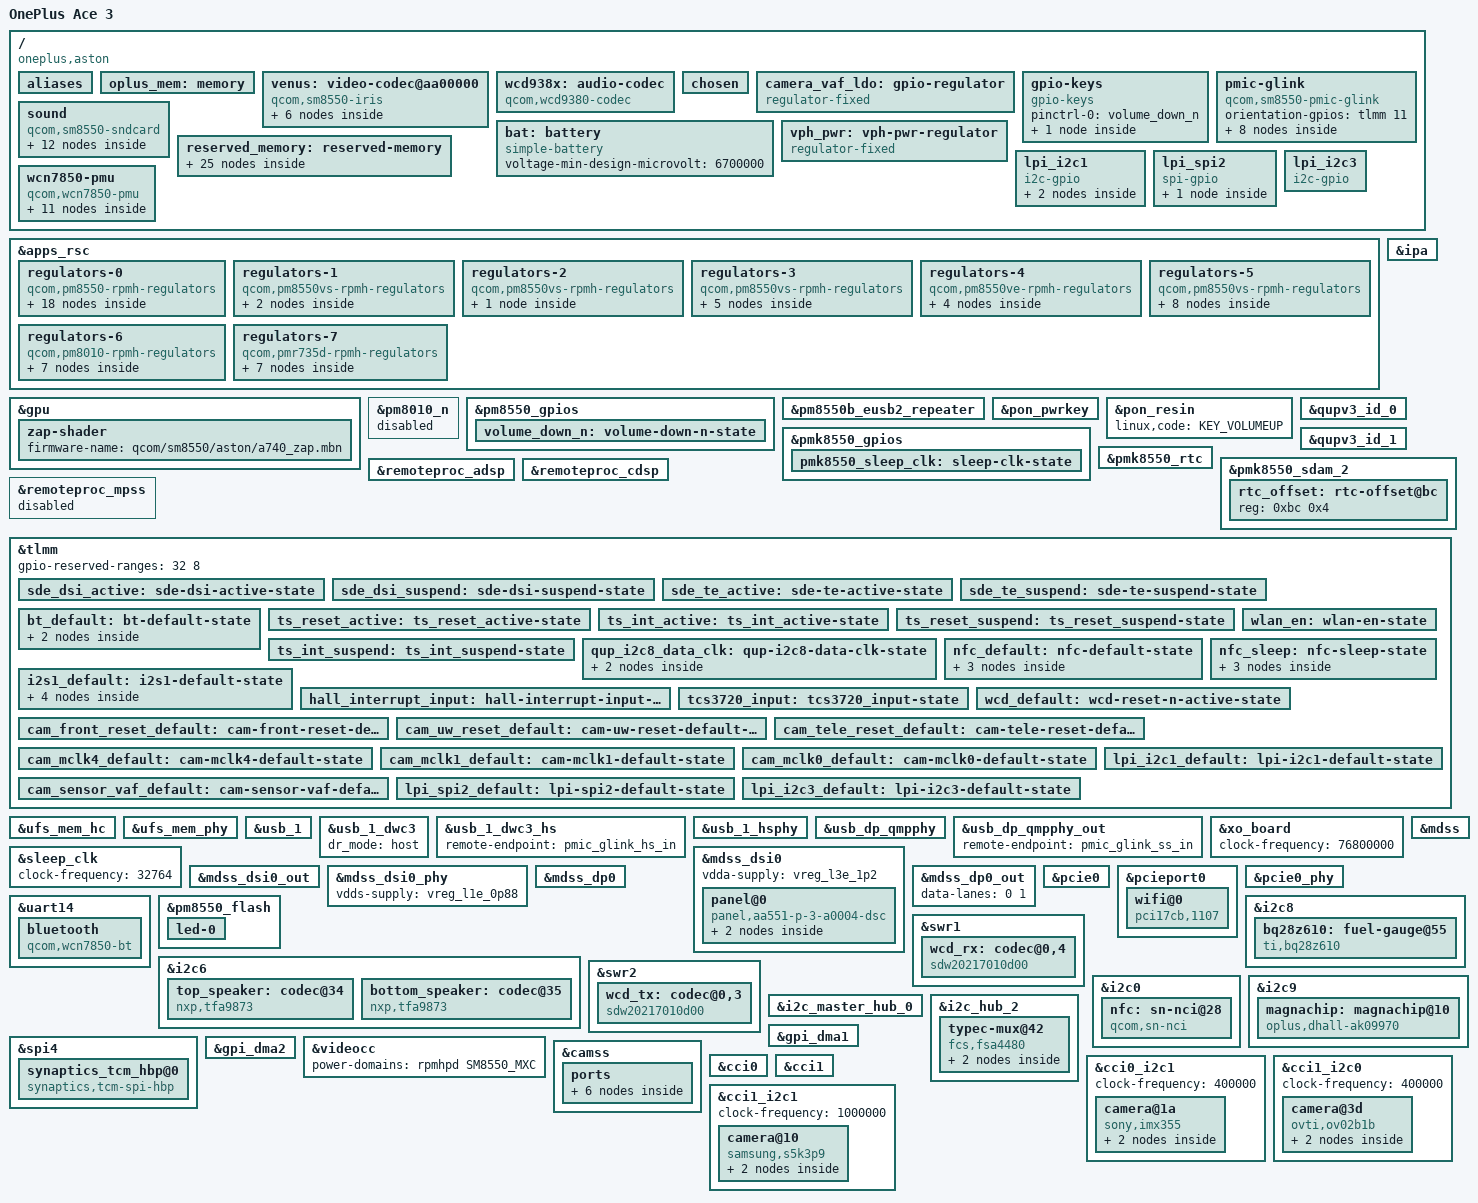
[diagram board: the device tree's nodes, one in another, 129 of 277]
// SPDX-License-Identifier: BSD-3-Clause
/*
 * Copyright (c) 2025, Shandorman <98683030+jiganomegsdfdf@users.noreply.github.com>
 */

/dts-v1/;

#include <dt-bindings/arm/qcom,ids.h>
#include <dt-bindings/regulator/qcom,rpmh-regulator.h>
#include <dt-bindings/leds/common.h>
#include <dt-bindings/interconnect/qcom,icc.h>
#include "sm8550.dtsi"
#include "pm8010.dtsi"
#include "pm8550.dtsi"
#include "pm8550b.dtsi"
#define PMK8550VE_SID 5
#include "pm8550ve.dtsi"
#include "pm8550vs.dtsi"
#include "pmk8550.dtsi"
#include "pmr735d_a.dtsi"

/delete-node/ &reserved_memory;

/ {
	model = "OnePlus Ace 3";
	compatible = "oneplus,aston", "qcom,sm8550";
	chassis-type = "handset";
	qcom,msm-id = <0x207 0x20000 0x207 0x10000 0x218 0x20000 0x218 0x10000>;
	qcom,board-id = <0x10008 0>;

	aliases {
		serial0 = &uart7;
		serial1 = &uart14;
	};
	
	oplus_mem: memory {
		ddr_device_type = <0x08>;
		device_type = "memory";
		reg = <0x00 0x80000000 0x00 0xe00000 0x00 0x811d0000 0x00 0x56e30000 0x00 0xd8140000 0x00 0x20000 0x00 0xd8800000 0x00 0x00 0x00 0xe1bb0000 0x00 0x1e450000 0x08 0x80000000 0x00 0x35700000 0x08 0xc0000000 0x01 0x40000000 0x0a 0x00 0x02 0x00>;
	};
	
	venus: video-codec@aa00000 {
		compatible = "qcom,sm8550-iris";
		reg = <0x0 0x0aa00000 0x0 0xf0000>;
		interrupts = <GIC_SPI 174 IRQ_TYPE_LEVEL_HIGH>;

		power-domains = <&videocc VIDEO_CC_MVS0C_GDSC>,
						<&videocc VIDEO_CC_MVS0_GDSC>,
						<&rpmhpd RPMHPD_MXC>,
						<&rpmhpd RPMHPD_MMCX>;
		power-domain-names = "venus", "vcodec0", "mxc", "mmcx";

		clocks = <&gcc GCC_VIDEO_AXI0_CLK>,
				 <&videocc VIDEO_CC_MVS0C_CLK>,
				 <&videocc VIDEO_CC_MVS0_CLK>;
		clock-names = "iface", "core", "vcodec0_core";

		interconnects = <&gem_noc MASTER_APPSS_PROC QCOM_ICC_TAG_ALWAYS
						 &config_noc SLAVE_VENUS_CFG QCOM_ICC_TAG_ALWAYS>,
						<&mmss_noc MASTER_VIDEO QCOM_ICC_TAG_ALWAYS
						 &mc_virt SLAVE_EBI1 QCOM_ICC_TAG_ALWAYS>;
		interconnect-names = "cpu-cfg", "video-mem";

		memory-region = <&video_mem>;

		resets = <&gcc GCC_VIDEO_AXI0_CLK_ARES>;
		reset-names = "bus";

		iommus = <&apps_smmu 0x1940 0x0000>,
				 <&apps_smmu 0x1947 0x0000>;
		dma-coherent;

		operating-points-v2 = <&iris_opp_table>;

		firmware-name = "qcom/sm8550/aston/vpu30_4v.mbn";

		iris_opp_table: opp-table {
			compatible = "operating-points-v2";

			opp-240000000 {
				opp-hz = /bits/ 64 <240000000>;
				required-opps = <&rpmhpd_opp_svs>,
								<&rpmhpd_opp_low_svs>;
			};

			opp-338000000 {
				opp-hz = /bits/ 64 <338000000>;
				required-opps = <&rpmhpd_opp_svs>,
								<&rpmhpd_opp_svs>;
			};

			opp-366000000 {
				opp-hz = /bits/ 64 <366000000>;
				required-opps = <&rpmhpd_opp_svs_l1>,
								<&rpmhpd_opp_svs_l1>;
			};

			opp-444000000 {
				opp-hz = /bits/ 64 <444000000>;
				required-opps = <&rpmhpd_opp_turbo>,
								<&rpmhpd_opp_turbo>;
			};

			opp-533333334 {
				opp-hz = /bits/ 64 <533333334>;
				required-opps = <&rpmhpd_opp_turbo_l1>,
								<&rpmhpd_opp_turbo_l1>;
			};
		};
	};

	wcd938x: audio-codec {
		compatible = "qcom,wcd9380-codec";
		
		pinctrl-names = "default";
		pinctrl-0 = <&wcd_default>;
		
		qcom,micbias1-microvolt = <2750000>;
		qcom,micbias2-microvolt = <2750000>;
		qcom,micbias3-microvolt = <2750000>;
		qcom,micbias4-microvolt = <2750000>;
		qcom,mbhc-buttons-vthreshold-microvolt = <75000 150000 237000 500000 500000 500000 500000 500000>;
		qcom,mbhc-headset-vthreshold-microvolt = <1700000>;
		qcom,mbhc-headphone-vthreshold-microvolt = <50000>;
		qcom,rx-device = <&wcd_rx>;
		qcom,tx-device = <&wcd_tx>;
		
		reset-gpios = <&tlmm 108 GPIO_ACTIVE_LOW>;
		
		vdd-buck-supply = <&vreg_l15b_1p8>;
		vdd-rxtx-supply = <&vreg_l15b_1p8>;
		vdd-io-supply = <&vreg_l15b_1p8>;
		vdd-mic-bias-supply = <&vreg_bob1>;
		
		#sound-dai-cells = <1>;
	};
	
	chosen {
		#address-cells = <2>;
		#size-cells = <2>;
		ranges;
	};

	camera_vaf_ldo: gpio-regulator {
		compatible = "regulator-fixed";
		regulator-name = "camera_vaf_ldo";
		regulator-min-microvolt = <2800000>;
		regulator-max-microvolt = <2800000>;
		regulator-enable-ramp-delay = <135>;
		enable-active-high;
		gpio = <&tlmm 52 0>;
		pinctrl-names = "default";
		pinctrl-0 = <&cam_sensor_vaf_default>;
	};

	gpio-keys {
		compatible = "gpio-keys";

		pinctrl-0 = <&volume_down_n>;
		pinctrl-names = "default";

		key-volume-down {
			label = "Volume Down";
			linux,code = <KEY_VOLUMEDOWN>;
			gpios = <&pm8550_gpios 6 GPIO_ACTIVE_LOW>;
			debounce-interval = <15>;
			linux,can-disable;
			wakeup-source;
		};
	};
	
	bat: battery {
		compatible = "simple-battery";
		voltage-min-design-microvolt = <6700000>;
	};

	pmic-glink {
		compatible = "qcom,sm8550-pmic-glink", "qcom,pmic-glink";
		#address-cells = <1>;
		#size-cells = <0>;
		orientation-gpios = <&tlmm 11 GPIO_ACTIVE_HIGH>;

		connector@0 {
			compatible = "usb-c-connector";
			reg = <0>;
			power-role = "dual";
			data-role = "dual";

			ports {
				#address-cells = <1>;
				#size-cells = <0>;

				port@0 {
					reg = <0>;

					pmic_glink_hs_in: endpoint {
						remote-endpoint = <&usb_1_dwc3_hs>;
					};
				};

				port@1 {
					reg = <1>;

					pmic_glink_ss_in: endpoint {
						remote-endpoint = <&usb_dp_qmpphy_out>;
					};
				};

				port@2 {
					reg = <2>;

					pmic_glink_sbu: endpoint {
						remote-endpoint = <&fsa4480_sbu_mux>;
					};
				};
			};
		};
	};
	
	sound {
		compatible = "qcom,sm8550-sndcard", "qcom,sm8450-sndcard";
		pinctrl-0 = <&i2s1_default>;
		pinctrl-names = "default";

		clocks = <&q6prmcc LPASS_CLK_ID_SEC_MI2S_IBIT LPASS_CLK_ATTRIBUTE_COUPLE_NO>;
		assigned-clocks = <&q6prmcc LPASS_CLK_ID_SEC_MI2S_IBIT LPASS_CLK_ATTRIBUTE_COUPLE_NO>;
		assigned-clock-rates = <1536000>;

		model = "astonsnd";
		audio-routing = "IN1_HPHL", "HPHL_OUT",
				"IN2_HPHR", "HPHR_OUT",
				"AMIC1", "MIC BIAS1",
				"AMIC2", "MIC BIAS2",
				"AMIC3", "MIC BIAS3",
				"AMIC4", "MIC BIAS4",
				"AMIC5", "MIC BIAS3",
				"TX SWR_INPUT0", "ADC1_OUTPUT",
				"TX SWR_INPUT1", "ADC2_OUTPUT",
				"TX SWR_INPUT0", "ADC3_OUTPUT",
				"TX SWR_INPUT1", "ADC4_OUTPUT";
		wcd-playback-dai-link {
			link-name = "WCD Playback";
			cpu {
				sound-dai = <&q6apmbedai RX_CODEC_DMA_RX_0>;
			};
			codec {
				sound-dai = <&wcd938x 0>, <&swr1 0>, <&lpass_rxmacro 0>;
			};
			platform {
				sound-dai = <&q6apm>;
			};
		};

		wcd-capture-dai-link {
			link-name = "WCD Capture";
			cpu {
				sound-dai = <&q6apmbedai TX_CODEC_DMA_TX_3>;
			};
			codec {
				sound-dai = <&wcd938x 1>, <&swr2 0>, <&lpass_txmacro 0>;
			};
			platform {
				sound-dai = <&q6apm>;
			};
		};

		secondary-i2s-dai-link {
			link-name = "Secondary MI2S Playback";

			cpu {
				sound-dai = <&q6apmbedai SECONDARY_MI2S_RX>;
			};

			platform {
				sound-dai = <&q6apm>;
			};

			codec {
				sound-dai = <&top_speaker>, <&bottom_speaker>;
			};
		};
	};
	
	reserved_memory: reserved-memory {
		#address-cells = <2>;
		#size-cells = <2>;
		ranges;
		
		hyp_mem: hyp-region@80000000 {
			no-map;
			reg = <0x00 0x80000000 0x00 0xa00000>;
		};

		cpusys_vm_mem: cpusys-vm-region@80a00000 {
			no-map;
			reg = <0x00 0x80a00000 0x00 0x400000>;
		};

		/* merged xbl_dt_log, xbl_ramdump, aop_image */
		xbl_dt_log_merged_mem: xbl-dt-log-merged-region@81a00000 {
			no-map;
			reg = <0x00 0x81a00000 0x00 0x260000>;
		};

		aop_cmd_db_mem: aop-cmd-db-region@81c60000 {
			compatible = "qcom,cmd-db";
			no-map;
			reg = <0x00 0x81c60000 0x00 0x20000>;
		};

		/* merged aop_config, tme_crash_dump, tme_log, uefi_log */
		aop_config_merged_mem: aop-config-merged-region@81c80000 {
			no-map;
			reg = <0x00 0x81c80000 0x00 0x74000>;
		};
		
		chipinfo_region: chipinfo-region@81cf4000 {
			no-map;
			reg = <0x00 0x81cf4000 0x00 0x1000>;
		};

		/* secdata region can be reused by apps */
		smem: smem@81d00000 {
			no-map;
			reg = <0x00 0x81d00000 0x00 0x200000>;
			hwlocks = <&tcsr_mutex 3>;
			compatible = "qcom,smem";
		};

		adsp_mhi_mem: adsp-mhi-region@81f00000 {
			no-map;
			reg = <0x00 0x81f00000 0x00 0x20000>;
		};
		
		tz_stat_region: tz-stat-region@82700000 {
			no-map;
			reg = <0x00 0x82700000 0x00 0x100000>;
		};
		
		mpss_mem: mpss-region@8a800000 {
			no-map;
			reg = <0x00 0x8a800000 0x00 0x10800000>;
		};

		q6_mpss_dtb_mem: q6-mpss-dtb-region@9b000000 {
			no-map;
			reg = <0x00 0x9b000000 0x00 0x80000>;
		};

		ipa_fw_mem: ipa-fw-region@9b080000 {
			no-map;
			reg = <0x00 0x9b080000 0x00 0x10000>;
		};

		ipa_gsi_mem: ipa-gsi-region@9b090000 {
			no-map;
			reg = <0x00 0x9b090000 0x00 0xa000>;
		};

		gpu_micro_code_mem: gpu-micro-code-region@9b09a000 {
			no-map;
			reg = <0x00 0x9b09a000 0x00 0x2000>;
		};
		
		video_mem: video-region@9bb00000 {
			no-map;
			reg = <0x00 0x9bb00000 0x00 0x700000>;
		};

		cdsp_mem: cdsp-region@9c900000 {
			no-map;
			reg = <0x00 0x9c900000 0x00 0x2000000>;
		};

		q6_cdsp_dtb_mem: q6-cdsp-dtb-region@9e900000 {
			no-map;
			reg = <0x00 0x9e900000 0x00 0x80000>;
		};

		q6_adsp_dtb_mem: q6-adsp-dtb-region@9e980000 {
			no-map;
			reg = <0x00 0x9e980000 0x00 0x80000>;
		};

		adspslpi_mem: adspslpi-region@9ea00000 {
			no-map;
			reg = <0x00 0x9ea00000 0x00 0x4880000>;
		};

		mpss_dsm_mem: mpss-dsm-region@d4d00000 {
			no-map;
			reg = <0x00 0xd4d00000 0x00 0x3300000>;
		};

		xbl_sc_mem: xbl-sc-region@d8100000 {
			no-map;
			reg = <0x00 0xd8100000 0x00 0x40000>;
		};

		cpucp_fw_mem: cpucp-fw-region@d8140000 {
			no-map;
			reg = <0x00 0xd8140000 0x00 0x1c0000>;
		};

		qtee_mem: qtee-region@d8300000 {
			no-map;
			reg = <0x00 0xd8300000 0x00 0x500000>;
		};

		hwfence_shbuf: hwfence-shbuf-region@e6440000 {
			no-map;
			reg = <0x00 0xe6440000 0x00 0x2dd000>;
		};

		rmtfs_mem: rmtfs-region@e8100000 {
			compatible = "qcom,rmtfs-mem";
			reg = <0x0 0xe8100000 0x0 0x280000>;
			no-map;

			qcom,client-id = <1>;
			qcom,vmid = <QCOM_SCM_VMID_MSS_MSA>;
		};
	};

	vph_pwr: vph-pwr-regulator {
		compatible = "regulator-fixed";
		regulator-name = "vph_pwr";
		regulator-min-microvolt = <3700000>;
		regulator-max-microvolt = <3700000>;

		regulator-always-on;
		regulator-boot-on;
	};

	lpi_i2c1 {
		compatible = "i2c-gpio";
		#address-cells = <1>;
		#size-cells = <0>;
		pinctrl-0 = <&lpi_i2c1_default>;
		pinctrl-names = "default";

		sda-gpios = <&tlmm 190 (GPIO_ACTIVE_HIGH|GPIO_OPEN_DRAIN)>;
		scl-gpios = <&tlmm 191 (GPIO_ACTIVE_HIGH|GPIO_OPEN_DRAIN)>;
		
		mmc56x3@30 {
			reg = <0x30>;
			compatible = "memsic,mmc56x3";
		};
		
		tcs3720@39 {
			reg = <0x39>;
			compatible = "tcs3720";
			interrupt-parent = <&tlmm>;
			interrupts = <16 IRQ_TYPE_EDGE_FALLING>;
		};
	};
	
	lpi_spi2 {
		compatible = "spi-gpio";
		#address-cells = <1>;
		#size-cells = <0>;
		pinctrl-0 = <&lpi_spi2_default>;
		pinctrl-names = "default";

		miso-gpios = <&tlmm 192 GPIO_ACTIVE_HIGH>;
		mosi-gpios = <&tlmm 193 GPIO_ACTIVE_HIGH>;
		sck-gpios = <&tlmm 194 GPIO_ACTIVE_HIGH>;
		cs-gpios = <&tlmm 195 GPIO_ACTIVE_HIGH>;
		num-chipselects = <1>;

		bmi26x@0 {
			reg = <0>;
			compatible = "bosch,bmi260";
			spi-max-frequency = <9600000>;
			interrupt-parent = <&tlmm>;
			interrupts = <84 IRQ_TYPE_LEVEL_HIGH>;
			vdd-supply = <&vreg_l1b_1p8>;
			vddio-supply = <&vreg_l1b_1p8>;
		};
	};
	
	lpi_i2c3 {
		compatible = "i2c-gpio";
		#address-cells = <1>;
		#size-cells = <0>;
		pinctrl-0 = <&lpi_i2c3_default>;
		pinctrl-names = "default";

		sda-gpios = <&tlmm 196 (GPIO_ACTIVE_HIGH|GPIO_OPEN_DRAIN)>;
		scl-gpios = <&tlmm 197 (GPIO_ACTIVE_HIGH|GPIO_OPEN_DRAIN)>;
	};
	
	wcn7850-pmu {
		compatible = "qcom,wcn7850-pmu";

		pinctrl-names = "default";
		pinctrl-0 = <&wlan_en>, <&bt_default>, <&pmk8550_sleep_clk>;

		wlan-enable-gpios = <&tlmm 80 GPIO_ACTIVE_HIGH>;
		bt-enable-gpios = <&tlmm 81 GPIO_ACTIVE_HIGH>;

		vdd-supply = <&vreg_s5g_0p8>;
		vddio-supply = <&vreg_l15b_1p8>; 
		vddaon-supply = <&vreg_s2g_0p8>;
		vdddig-supply = <&vreg_s4e_0p9>;
		vddrfa1p2-supply = <&vreg_s4g_1p3>;
		vddrfa1p8-supply = <&vreg_s6g_1p8>;

		regulators {
			vreg_pmu_rfa_cmn: ldo0 {
				regulator-name = "vreg_pmu_rfa_cmn";
			};

			vreg_pmu_aon_0p59: ldo1 {
				regulator-name = "vreg_pmu_aon_0p59";
			};

			vreg_pmu_wlcx_0p8: ldo2 {
				regulator-name = "vreg_pmu_wlcx_0p8";
			};

			vreg_pmu_wlmx_0p85: ldo3 {
				regulator-name = "vreg_pmu_wlmx_0p85";
			};

			vreg_pmu_btcmx_0p85: ldo4 {
				regulator-name = "vreg_pmu_btcmx_0p85";
			};

			vreg_pmu_rfa_0p8: ldo5 {
				regulator-name = "vreg_pmu_rfa_0p8";
			};

			vreg_pmu_rfa_1p2: ldo6 {
				regulator-name = "vreg_pmu_rfa_1p2";
			};

			vreg_pmu_rfa_1p8: ldo7 {
				regulator-name = "vreg_pmu_rfa_1p8";
			};

			vreg_pmu_pcie_0p9: ldo8 {
				regulator-name = "vreg_pmu_pcie_0p9";
			};

			vreg_pmu_pcie_1p8: ldo9 {
				regulator-name = "vreg_pmu_pcie_1p8";
			};
		};
	};
};

&apps_rsc {
	regulators-0 {
		compatible = "qcom,pm8550-rpmh-regulators";
		qcom,pmic-id = "b";

		vdd-bob1-supply = <&vph_pwr>;
		vdd-bob2-supply = <&vph_pwr>;
		vdd-l1-l4-l10-supply = <&vreg_s6g_1p8>;
		vdd-l2-l13-l14-supply = <&vreg_bob1>;
		vdd-l3-supply = <&vreg_s4g_1p3>;
		vdd-l5-l16-supply = <&vreg_bob1>;
		vdd-l6-l7-supply = <&vreg_bob1>;
		vdd-l8-l9-supply = <&vreg_bob1>;
		vdd-l11-supply = <&vreg_s4g_1p3>;
		vdd-l12-supply = <&vreg_s6g_1p8>;
		vdd-l15-supply = <&vreg_s6g_1p8>;
		vdd-l17-supply = <&vreg_bob2>;

		vreg_bob1: bob1 {
			regulator-name = "vreg_bob1";
			regulator-min-microvolt = <3008000>;
			regulator-max-microvolt = <3960000>;
			regulator-initial-mode = <RPMH_REGULATOR_MODE_HPM>;
		};

		vreg_bob2: bob2 {
			regulator-name = "vreg_bob2";
			regulator-min-microvolt = <2720000>;
			regulator-max-microvolt = <3008000>;
			regulator-initial-mode = <RPMH_REGULATOR_MODE_HPM>;
		};

		vreg_l1b_1p8: ldo1 {
			regulator-name = "vreg_l1b_1p8";
			regulator-min-microvolt = <1800000>;
			regulator-max-microvolt = <1800000>;
			regulator-initial-mode = <RPMH_REGULATOR_MODE_HPM>;
		};

		vreg_l2b_3p0: ldo2 {
			regulator-name = "vreg_l2b_3p0";
			regulator-min-microvolt = <3008000>;
			regulator-max-microvolt = <3008000>;
			regulator-initial-mode = <RPMH_REGULATOR_MODE_HPM>;
		};

		vreg_l4b_1p8: ldo4 {
			regulator-name = "vreg_l4b_1p8";
			regulator-min-microvolt = <1800000>;
			regulator-max-microvolt = <1800000>;
			regulator-initial-mode = <RPMH_REGULATOR_MODE_HPM>;
		};

		vreg_l5b_3p1: ldo5 {
			regulator-name = "vreg_l5b_3p1";
			regulator-min-microvolt = <3104000>;
			regulator-max-microvolt = <3104000>;
			regulator-initial-mode = <RPMH_REGULATOR_MODE_HPM>;
		};

		vreg_l6b_1p8: ldo6 {
			regulator-name = "vreg_l6b_1p8";
			regulator-min-microvolt = <1800000>;
			regulator-max-microvolt = <3008000>;
			regulator-initial-mode = <RPMH_REGULATOR_MODE_HPM>;
		};

		vreg_l7b_1p8: ldo7 {
			regulator-name = "vreg_l7b_1p8";
			regulator-min-microvolt = <1800000>;
			regulator-max-microvolt = <3008000>;
			regulator-initial-mode = <RPMH_REGULATOR_MODE_HPM>;
		};

		vreg_l8b_1p8: ldo8 {
			regulator-name = "vreg_l8b_1p8";
			regulator-min-microvolt = <1800000>;
			regulator-max-microvolt = <1800000>;
			regulator-initial-mode = <RPMH_REGULATOR_MODE_HPM>;
			regulator-always-on;
			regulator-boot-on;
		};

		vreg_l9b_3p3: ldo9 {
			regulator-name = "vreg_l9b_3p3";
			regulator-min-microvolt = <2960000>;
			regulator-max-microvolt = <3008000>;
			regulator-initial-mode = <RPMH_REGULATOR_MODE_HPM>;
		};

		vreg_l10b_1p8: ldo10 {
			regulator-name = "vreg_l10b_1p8";
			regulator-min-microvolt = <1800000>;
			regulator-max-microvolt = <1800000>;
			regulator-initial-mode = <RPMH_REGULATOR_MODE_HPM>;
			regulator-always-on;
		};

		vreg_l11b_1p2: ldo11 {
			regulator-name = "vreg_l11b_1p2";
			regulator-min-microvolt = <1200000>;
			regulator-max-microvolt = <1504000>;
			regulator-initial-mode = <RPMH_REGULATOR_MODE_HPM>;
		};

		vreg_l12b_1p8: ldo12 {
			regulator-name = "vreg_l12b_1p8";
			regulator-min-microvolt = <1800000>;
			regulator-max-microvolt = <1800000>;
			regulator-initial-mode = <RPMH_REGULATOR_MODE_HPM>;
		};

		vreg_l13b_3p3: ldo13 {
			regulator-name = "vreg_l13b_3p3";
			regulator-min-microvolt = <3000000>;
			regulator-max-microvolt = <3200000>;
			regulator-initial-mode = <RPMH_REGULATOR_MODE_HPM>;
		};

		vreg_l14b_3p2: ldo14 {
			regulator-name = "vreg_l14b_3p2";
			regulator-min-microvolt = <2800000>;
			regulator-max-microvolt = <3200000>;
			regulator-initial-mode = <RPMH_REGULATOR_MODE_HPM>;
		};
		
		vreg_l15b_1p8: ldo15 {
			regulator-name = "vreg_l15b_1p8";
			regulator-min-microvolt = <1800000>;
			regulator-max-microvolt = <1800000>;
			regulator-initial-mode = <RPMH_REGULATOR_MODE_HPM>;
			regulator-always-on;
		};

		vreg_l16b_2p8: ldo16 {
			regulator-name = "vreg_l16b_2p8";
			regulator-min-microvolt = <2800000>;
			regulator-max-microvolt = <2800000>;
			regulator-initial-mode = <RPMH_REGULATOR_MODE_HPM>;
		};

		vreg_l17b_2p5: ldo17 {
			regulator-name = "vreg_l17b_2p5";
			regulator-min-microvolt = <2504000>;
			regulator-max-microvolt = <2504000>;
			regulator-initial-mode = <RPMH_REGULATOR_MODE_HPM>;
		};
	};

	regulators-1 {
		compatible = "qcom,pm8550vs-rpmh-regulators";
		qcom,pmic-id = "c";

		vdd-l3-supply = <&vreg_s4e_0p9>;
		
		
		vreg_l1c_0p91: ldo1 {
			regulator-name = "vreg_l1c_0p9";
			regulator-min-microvolt = <1200000>;
			regulator-max-microvolt = <1200000>;
			regulator-initial-mode = <RPMH_REGULATOR_MODE_HPM>;
		};

		vreg_l3c_0p91: ldo3 {
			regulator-name = "vreg_l3c_0p9";
			regulator-min-microvolt = <880000>;
			regulator-max-microvolt = <912000>;
			regulator-initial-mode = <RPMH_REGULATOR_MODE_HPM>;
		};
	};

	regulators-2 {
		compatible = "qcom,pm8550vs-rpmh-regulators";
		qcom,pmic-id = "d";

		vdd-l1-supply = <&vreg_s4e_0p9>;

		vreg_l1d_0p88: ldo1 {
			regulator-name = "vreg_l1d_0p88";
			regulator-min-microvolt = <880000>;
			regulator-max-microvolt = <920000>;
			regulator-initial-mode = <RPMH_REGULATOR_MODE_HPM>;
		};
	};

	regulators-3 {
		compatible = "qcom,pm8550vs-rpmh-regulators";
		qcom,pmic-id = "e";

		vdd-l1-supply = <&vreg_s4e_0p9>;
		vdd-l2-supply = <&vreg_s4e_0p9>;
		vdd-l3-supply = <&vreg_s4g_1p3>;
		vdd-s4-supply = <&vph_pwr>;
		vdd-s5-supply = <&vph_pwr>;

		vreg_s4e_0p9: smps4 {
			regulator-name = "vreg_s4e_0p9";
			regulator-min-microvolt = <904000>;
			regulator-max-microvolt = <984000>;
			regulator-initial-mode = <RPMH_REGULATOR_MODE_HPM>;
		};

		vreg_s5e_1p1: smps5 {
			regulator-name = "vreg_s5e_1p1";
			regulator-min-microvolt = <1008000>;
			regulator-max-microvolt = <1120000>;
			regulator-initial-mode = <RPMH_REGULATOR_MODE_HPM>;
		};

		vreg_l1e_0p88: ldo1 {
			regulator-name = "vreg_l1e_0p88";
			regulator-min-microvolt = <880000>;
			regulator-max-microvolt = <912000>;
			regulator-initial-mode = <RPMH_REGULATOR_MODE_HPM>;
		};

		vreg_l2e_0p9: ldo2 {
			regulator-name = "vreg_l2e_0p9";
			regulator-min-microvolt = <864000>;
			regulator-max-microvolt = <970000>;
			regulator-initial-mode = <RPMH_REGULATOR_MODE_HPM>;
		};

		vreg_l3e_1p2: ldo3 {
			regulator-name = "vreg_l3e_1p2";
			regulator-min-microvolt = <1200000>;
			regulator-max-microvolt = <1200000>;
			regulator-initial-mode = <RPMH_REGULATOR_MODE_HPM>;
		};
	};

	regulators-4 {
		compatible = "qcom,pm8550ve-rpmh-regulators";
		qcom,pmic-id = "f";

		vdd-l1-supply = <&vreg_s4e_0p9>;
		vdd-l2-supply = <&vreg_s4e_0p9>;
		vdd-l3-supply = <&vreg_s4e_0p9>;
		vdd-s4-supply = <&vph_pwr>;

		vreg_s4f_0p5: smps4 {
			regulator-name = "vreg_s4f_0p5";
			regulator-min-microvolt = <300000>;
			regulator-max-microvolt = <700000>;
			regulator-initial-mode = <RPMH_REGULATOR_MODE_HPM>;
		};

		vreg_l1f_0p9: ldo1 {
			regulator-name = "vreg_l1f_0p9";
			regulator-min-microvolt = <880000>;
			regulator-max-microvolt = <912000>;
			regulator-initial-mode = <RPMH_REGULATOR_MODE_HPM>;
		};

		vreg_l2f_0p88: ldo2 {
			regulator-name = "vreg_l2f_0p88";
			regulator-min-microvolt = <880000>;
			regulator-max-microvolt = <912000>;
			regulator-initial-mode = <RPMH_REGULATOR_MODE_HPM>;
		};

		vreg_l3f_0p91: ldo3 {
			regulator-name = "vreg_l3f_0p91";
			regulator-min-microvolt = <880000>;
			regulator-max-microvolt = <912000>;
			regulator-initial-mode = <RPMH_REGULATOR_MODE_HPM>;
		};
	};

	regulators-5 {
		compatible = "qcom,pm8550vs-rpmh-regulators";
		qcom,pmic-id = "g";

		vdd-l1-supply = <&vreg_s4g_1p3>;
		vdd-l2-supply = <&vreg_s4g_1p3>;
		vdd-l3-supply = <&vreg_s4g_1p3>;
		vdd-s1-supply = <&vph_pwr>;
		vdd-s2-supply = <&vph_pwr>;
		vdd-s3-supply = <&vph_pwr>;
		vdd-s4-supply = <&vph_pwr>;
		vdd-s5-supply = <&vph_pwr>;
		vdd-s6-supply = <&vph_pwr>;

		vreg_s1g_1p2: smps1 {
			regulator-name = "vreg_s1g_1p2";
			regulator-min-microvolt = <1200000>;
			regulator-max-microvolt = <1300000>;
			regulator-initial-mode = <RPMH_REGULATOR_MODE_HPM>;
		};

		vreg_s2g_0p8: smps2 {
			regulator-name = "vreg_s2g_0p8";
			regulator-min-microvolt = <500000>;
			regulator-max-microvolt = <1036000>;
			regulator-initial-mode = <RPMH_REGULATOR_MODE_HPM>;
		};

		vreg_s4g_1p3: smps4 {
			regulator-name = "vreg_s4g_1p3";
			regulator-min-microvolt = <1200000>;
			regulator-max-microvolt = <1352000>;
			regulator-initial-mode = <RPMH_REGULATOR_MODE_HPM>;
		};

		vreg_s5g_0p8: smps5 {
			regulator-name = "vreg_s5g_0p8";
			regulator-min-microvolt = <500000>;
			regulator-max-microvolt = <1004000>;
			regulator-initial-mode = <RPMH_REGULATOR_MODE_HPM>;
		};

		vreg_s6g_1p8: smps6 {
			regulator-name = "vreg_s6g_1p8";
			regulator-min-microvolt = <1800000>;
			regulator-max-microvolt = <2000000>;
			regulator-initial-mode = <RPMH_REGULATOR_MODE_HPM>;
		};

		vreg_l1g_1p2: ldo1 {
			regulator-name = "vreg_l1g_1p2";
			regulator-min-microvolt = <1144000>;
			regulator-max-microvolt = <1256000>;
			regulator-initial-mode = <RPMH_REGULATOR_MODE_HPM>;
		};

		vreg_l2g_1p2: ldo2 {
			regulator-name = "vreg_l2g_1p2";
			regulator-min-microvolt = <1056000>;
			regulator-max-microvolt = <1056000>;
			regulator-initial-mode = <RPMH_REGULATOR_MODE_HPM>;
		};

		vreg_l3g_1p2: ldo3 {
			regulator-name = "vreg_l3g_1p2";
			regulator-min-microvolt = <1200000>;
			regulator-max-microvolt = <1200000>;
			regulator-initial-mode = <RPMH_REGULATOR_MODE_HPM>;
		};
	};

	regulators-6 {
		compatible = "qcom,pm8010-rpmh-regulators";
		qcom,pmic-id = "m";

		vdd-l1-l2-supply = <&vreg_s4g_1p3>;
		vdd-l3-l4-supply = <&vreg_bob2>;
		vdd-l5-supply = <&vreg_s6g_1p8>;
		vdd-l6-supply = <&vreg_s6g_1p8>;
		vdd-l7-supply = <&vreg_bob1>;

		vreg_l1m_1p2: ldo1 {
			regulator-name = "vreg_l1m_1p2";
			regulator-min-microvolt = <1200000>;
			regulator-max-microvolt = <1200000>;
			regulator-initial-mode = <RPMH_REGULATOR_MODE_HPM>;
		};

		vreg_l2m_1p08: ldo2 {
			regulator-name = "vreg_l2m_1p08";
			regulator-min-microvolt = <1200000>;
			regulator-max-microvolt = <1200000>;
			regulator-initial-mode = <RPMH_REGULATOR_MODE_HPM>;
		};

		vreg_l3m_2p8: ldo3 {
			regulator-name = "vreg_l3m_2p8";
			regulator-min-microvolt = <2800000>;
			regulator-max-microvolt = <2800000>;
			regulator-initial-mode = <RPMH_REGULATOR_MODE_HPM>;
		};

		vreg_l4m_2p8: ldo4 {
			regulator-name = "vreg_l4m_2p8";
			regulator-min-microvolt = <2800000>;
			regulator-max-microvolt = <2800000>;
			regulator-initial-mode = <RPMH_REGULATOR_MODE_HPM>;
		};

		vreg_l5m_1p8: ldo5 {
			regulator-name = "vreg_l5m_1p8";
			regulator-min-microvolt = <1800000>;
			regulator-max-microvolt = <1800000>;
			regulator-initial-mode = <RPMH_REGULATOR_MODE_HPM>;
		};

		vreg_l6m_2p8: ldo6 {
			regulator-name = "vreg_l6m_2p8";
			regulator-min-microvolt = <2848000>;
			regulator-max-microvolt = <2848000>;
			regulator-initial-mode = <RPMH_REGULATOR_MODE_HPM>;
		};

		vreg_l7m_2p85: ldo7 {
			regulator-name = "vreg_l7m_2p85";
			regulator-min-microvolt = <2800000>;
			regulator-max-microvolt = <2800000>;
			regulator-initial-mode = <RPMH_REGULATOR_MODE_HPM>;
		};
	};

	regulators-7 {
		compatible = "qcom,pmr735d-rpmh-regulators";
		qcom,pmic-id = "k";

		vdd-l1-l2-l5-supply = <&vreg_s2g_0p8>;
		vdd-l3-l4-supply = <&vreg_s1g_1p2>;
		vdd-l6-supply  = <&vreg_s6g_1p8>;
		vdd-l7-supply = <&vreg_s1g_1p2>;

		vreg_l1k_0p4: ldo1 {
			regulator-name = "vreg_l1k_0p4";
			regulator-min-microvolt = <400000>;
			regulator-max-microvolt = <900000>;
			regulator-initial-mode = <RPMH_REGULATOR_MODE_HPM>;
		};

		vreg_l2k_0p5: ldo2 {
			regulator-name = "vreg_l2k_0p5";
			regulator-min-microvolt = <500000>;
			regulator-max-microvolt = <900000>;
			regulator-initial-mode = <RPMH_REGULATOR_MODE_HPM>;
		};

		vreg_l3k_0p88: ldo3 {
			regulator-name = "vreg_l3k_0p88";
			regulator-min-microvolt = <880000>;
			regulator-max-microvolt = <912000>;
			regulator-initial-mode = <RPMH_REGULATOR_MODE_HPM>;
		};

		vreg_l4k_1p2: ldo4 {
			regulator-name = "vreg_l4k_1p2";
			regulator-min-microvolt = <1200000>;
			regulator-max-microvolt = <1200000>;
			regulator-initial-mode = <RPMH_REGULATOR_MODE_HPM>;
		};

		vreg_l5k_0p8: ldo5 {
			regulator-name = "vreg_l5k_0p8";
			regulator-min-microvolt = <800000>;
			regulator-max-microvolt = <800000>;
			regulator-initial-mode = <RPMH_REGULATOR_MODE_HPM>;
		};

		vreg_l6k_1p77: ldo6 {
			regulator-name = "vreg_l6k_1p77";
			regulator-min-microvolt = <1776000>;
			regulator-max-microvolt = <1900000>;
			regulator-initial-mode = <RPMH_REGULATOR_MODE_HPM>;
		};

		vreg_l7k_1p2: ldo7 {
			regulator-name = "vreg_l7k_1p2";
			regulator-min-microvolt = <1200000>;
			regulator-max-microvolt = <1200000>;
			regulator-initial-mode = <RPMH_REGULATOR_MODE_HPM>;
		};
	};
};



&ipa {
	qcom,gsi-loader = "self";
	memory-region = <&ipa_fw_mem>;
	firmware-name = "qcom/sm8550/aston/ipa_fws.mbn";
	status = "okay";
};

&gpu {
	status = "okay";

	zap-shader {
		firmware-name = "qcom/sm8550/aston/a740_zap.mbn";
	};
};

&pm8010_n {
	status = "disabled";
};

&pm8550_gpios {
	volume_down_n: volume-down-n-state {
		pins = "gpio6";
		function = "normal";
		power-source = <1>;
		bias-pull-up;
		input-enable;
	};
};

&pm8550b_eusb2_repeater {
	vdd18-supply = <&vreg_l15b_1p8>;
	vdd3-supply = <&vreg_l5b_3p1>;
};

&pon_pwrkey {
	status = "okay";
	interrupts = <0x0 0x13 0x7 IRQ_TYPE_EDGE_BOTH>;
    linux,code = <KEY_POWER>;
};

&pon_resin {
	linux,code = <KEY_VOLUMEUP>;

	status = "okay";
};

&pmk8550_gpios {
	pmk8550_sleep_clk: sleep-clk-state {
		pins = "gpio3";
		function = "func1";
		input-disable;
		output-enable;
		bias-disable;
		power-source = <0>;
	};
};

&qupv3_id_0 {
	status = "okay";
};

&qupv3_id_1 {
	status = "okay";
};

&pmk8550_rtc {
	nvmem-cells = <&rtc_offset>;
	nvmem-cell-names = "offset";
};

&pmk8550_sdam_2 {
	rtc_offset: rtc-offset@bc {
		reg = <0xbc 0x4>;
	};
};

&remoteproc_adsp {
	firmware-name = "qcom/sm8550/aston/adsp.mbn",
			"qcom/sm8550/aston/adsp_dtb.mbn";
	status = "okay";
};

&remoteproc_cdsp {
	firmware-name = "qcom/sm8550/aston/cdsp.mbn",
			"qcom/sm8550/aston/cdsp_dtb.mbn";
	status = "okay";
};

&remoteproc_mpss {
	firmware-name = "qcom/sm8550/aston/modem.mbn",
			"qcom/sm8550/aston/modem_dtb.mbn";
	status = "disabled";
};

&tlmm {
	gpio-reserved-ranges = <32 8>;

	sde_dsi_active: sde-dsi-active-state {
		pins = "gpio133";
		function = "gpio";
		drive-strength = <8>;
		bias-disable;
	};

	sde_dsi_suspend: sde-dsi-suspend-state {
		pins = "gpio133";
		function = "gpio";
		drive-strength = <2>;
		bias-pull-down;
	};

	sde_te_active: sde-te-active-state {
		pins = "gpio86";
		function = "mdp_vsync";
		drive-strength = <2>;
		bias-pull-down;
	};

	sde_te_suspend: sde-te-suspend-state {
		pins = "gpio86";
		function = "mdp_vsync";
		drive-strength = <2>;
		bias-pull-down;
	};

	bt_default: bt-default-state {
		bt-en-pins {
			pins = "gpio81";
			function = "gpio";
			drive-strength = <16>;
			bias-disable;
		};

		sw-ctrl-pins {
			pins = "gpio82";
			function = "gpio";
			bias-pull-down;
		};
	};

	ts_reset_active: ts_reset_active-state {
		pins = "gpio24";
		function = "gpio";
		bias-disable;
		output-low;
		drive-strength = <8>;
	};

	ts_int_active: ts_int_active-state {
		pins = "gpio25";
		function = "gpio";
		bias-pull-up;
		drive-strength = <8>;
		input-enable;
	};

	ts_reset_suspend: ts_reset_suspend-state {
		pins = "gpio24";
		function = "gpio";
		bias-pull-down;
		drive-strength = <2>;
	};

	ts_int_suspend: ts_int_suspend-state {
		pins = "gpio25";
		function = "gpio";
		bias-pull-down;
		drive-strength = <2>;
	};

	wlan_en: wlan-en-state {
		pins = "gpio80";
		function = "gpio";
		drive-strength = <8>;
		bias-pull-down;
	};

	qup_i2c8_data_clk: qup-i2c8-data-clk-state {
		scl-pins {
			pins = "gpio1";
			function = "qup2_se0_l1_mirb";
			drive-strength = <2>;
			bias-pull-up = <2200>;
		};

		sda-pins {
			pins = "gpio0";
			function = "qup2_se0_l0_mirb";
			drive-strength = <2>;
			bias-pull-up = <2200>;
		};
	};

	nfc_default: nfc-default-state {
		nfc_int_active: nfc_int_active-state {
			pins = "gpio55";
			function = "gpio";
			drive-strength = <2>;
			bias-pull-up;
		};

		nfc_enable_active: nfc_enable_active-state {
			pins = "gpio30";
			function = "gpio";
			drive-strength = <2>;
			bias-pull-up;
		};

		nfc_clk_req_active: nfc_clk_req_active-state {
			pins = "gpio31";
			function = "gpio";
			drive-strength = <2>;
			bias-pull-up;
		};
	};

	nfc_sleep: nfc-sleep-state {
		nfc_int_suspend: nfc_int_suspend-state {
			pins = "gpio55";
			function = "gpio";
			drive-strength = <2>;
			bias-pull-up;
		};

		nfc_enable_suspend: nfc_enable_suspend-state {
			pins = "gpio30";
			function = "gpio";
			drive-strength = <2>;
			bias-disable;
		};

		nfc_clk_req_suspend: nfc_clk_req_suspend-state {
			pins = "gpio31";
			function = "gpio";
			drive-strength = <2>;
			bias-disable;
		};
	};

	i2s1_default: i2s1-default-state {
		sck-pins {
			pins = "gpio121";
			function = "i2s1_sck";
			drive-strength = <8>;
			bias-disable;
			output-high;
		};

		data0-pins {
			pins = "gpio122";
			function = "i2s1_data0";
			drive-strength = <8>;
			bias-disable;
		};

		ws-pins {
			pins = "gpio123";
			function = "i2s1_ws";
			drive-strength = <8>;
			bias-disable;
			output-high;
		};

		data1-pins {
			pins = "gpio124";
			function = "i2s1_data1";
			drive-strength = <8>;
			bias-disable;
			output-high;
		};
	};

	hall_interrupt_input: hall-interrupt-input-state {
		pins = "gpio17";
		function = "gpio";
		drive-strength = <2>;
		bias-pull-up;
	};

	tcs3720_input: tcs3720_input-state {
		pins = "gpio16";
		function = "gpio";
		drive-strength = <2>;
		bias-disable;
	};

	wcd_default: wcd-reset-n-active-state {
		pins = "gpio108";
		function = "gpio";
		drive-strength = <16>;
		bias-disable;
		output-low;
	};

	cam_front_reset_default: cam-front-reset-default-state {
		pins = "gpio120";
		function = "gpio";
		drive-strength = <2>;
		bias-disable;
	};

	cam_uw_reset_default: cam-uw-reset-default-state {
		pins = "gpio118";
		function = "gpio";
		drive-strength = <2>;
		bias-disable;
	};

	cam_tele_reset_default: cam-tele-reset-default-state {
		pins = "gpio119";
		function = "gpio";
		drive-strength = <2>;
		bias-disable;
	};

	cam_mclk4_default: cam-mclk4-default-state {
		pins = "gpio104";
		function = "cam_aon_mclk4";
		drive-strength = <4>;
		bias-disable;
	};

	cam_mclk1_default: cam-mclk1-default-state {
		pins = "gpio101";
		function = "cam_mclk";
		drive-strength = <4>;
		bias-disable;
	};

	cam_mclk0_default: cam-mclk0-default-state {
		pins = "gpio100";
		function = "cam_mclk";
		drive-strength = <4>;
		bias-disable;
	};

	cam_sensor_vaf_default: cam-sensor-vaf-default-state {
		pins = "gpio52";
		function = "gpio";
		bias-disable;
		drive-strength = <2>;
	};

	lpi_i2c1_default: lpi-i2c1-default-state {
		/* SDA, SCL */
		pins = "gpio190", "gpio191";
		function = "gpio";
	};

	lpi_spi2_default: lpi-spi2-default-state {
		/* MISO, MOSI, CLK, CS */
		pins = "gpio192", "gpio193", "gpio194", "gpio195";
		function = "gpio";
	};

	lpi_i2c3_default: lpi-i2c3-default-state {
		/* SDA, SCL */
		pins = "gpio196", "gpio197";
		function = "gpio";
	};
};

&ufs_mem_hc {
	reset-gpios = <&tlmm 210 GPIO_ACTIVE_LOW>;
	vcc-supply = <&vreg_l17b_2p5>;
	vcc-max-microamp = <1300000>;
	vccq-supply = <&vreg_l1g_1p2>;
	vccq-max-microamp = <1200000>;
	vdd-hba-supply = <&vreg_l3g_1p2>;

	status = "okay";
};

&ufs_mem_phy {
	vdda-phy-supply = <&vreg_l1d_0p88>;
	vdda-pll-supply = <&vreg_l3e_1p2>;

	status = "okay";
};

&usb_1 {
	status = "okay";
};

&usb_1_dwc3 {
	dr_mode = "host";
};

&usb_1_dwc3_hs {
	remote-endpoint = <&pmic_glink_hs_in>;
};

&usb_1_hsphy {
	vdd-supply = <&vreg_l1e_0p88>;
	vdda12-supply = <&vreg_l3e_1p2>;

	phys = <&pm8550b_eusb2_repeater>;
	status = "okay";
};

&usb_dp_qmpphy {
	vdda-phy-supply = <&vreg_l3e_1p2>;
	vdda-pll-supply = <&vreg_l3f_0p91>;

	status = "okay";
};

&usb_dp_qmpphy_out {
	remote-endpoint = <&pmic_glink_ss_in>;
};

&xo_board {
	clock-frequency = <76800000>;
};

&sleep_clk {
	clock-frequency = <32764>;
};

&mdss {
	status = "okay";
};

&mdss_dsi0 {
	vdda-supply = <&vreg_l3e_1p2>;
	status = "okay";
	
	panel@0 {
		compatible = "panel,aa551-p-3-a0004-dsc";
		reg = <0>;
		
		pinctrl-names = "default", "sleep";
		pinctrl-0 = <&sde_dsi_active>, <&sde_te_active>;
		pinctrl-1 = <&sde_dsi_suspend>, <&sde_te_suspend>;

		vddio-supply = <&vreg_l12b_1p8>;
		vci-supply = <&vreg_l13b_3p3>;
		
		reset-gpios = <&tlmm 133 GPIO_ACTIVE_LOW>;

		port {
			panel_in: endpoint {
				remote-endpoint = <&mdss_dsi0_out>;
			};
		};
	};
};

&mdss_dsi0_out {
	status = "okay";
	data-lanes = <0 1 2 3>;
	remote-endpoint = <&panel_in>;
};

&mdss_dsi0_phy {
	vdds-supply = <&vreg_l1e_0p88>;
	status = "okay";
};

&mdss_dp0 {
	status = "okay";
};

&mdss_dp0_out {
	data-lanes = <0 1>;
};

&pcie0 {
	wake-gpios = <&tlmm 96 GPIO_ACTIVE_HIGH>;
	perst-gpios = <&tlmm 94 GPIO_ACTIVE_LOW>;

	pinctrl-names = "default";
	pinctrl-0 = <&pcie0_default_state>;

	status = "okay";
};

&pcieport0 {
	status = "okay";
	
	wifi@0 {
		compatible = "pci17cb,1107";
		reg = <0x10000 0x0 0x0 0x0 0x0>;

		vddrfacmn-supply = <&vreg_pmu_rfa_cmn>;
		vddaon-supply = <&vreg_pmu_aon_0p59>;
		vddwlcx-supply = <&vreg_pmu_wlcx_0p8>;
		vddwlmx-supply = <&vreg_pmu_wlmx_0p85>;
		vddrfa0p8-supply = <&vreg_pmu_rfa_0p8>;
		vddrfa1p2-supply = <&vreg_pmu_rfa_1p2>;
		vddrfa1p8-supply = <&vreg_pmu_rfa_1p8>;
		vddpcie0p9-supply = <&vreg_pmu_pcie_0p9>;
		vddpcie1p8-supply = <&vreg_pmu_pcie_1p8>;
		status = "okay";
	};
};

&pcie0_phy {
	vdda-phy-supply = <&vreg_l1e_0p88>;
	vdda-pll-supply = <&vreg_l3e_1p2>;

	status = "okay";
};

&uart14 {
	status = "okay";

	bluetooth {
		compatible = "qcom,wcn7850-bt";

		local-bd-address = [ c2 59 96 e0 ca 00 ];

		vddrfacmn-supply = <&vreg_pmu_rfa_cmn>;
		vddaon-supply = <&vreg_pmu_aon_0p59>;
		vddwlcx-supply = <&vreg_pmu_wlcx_0p8>;
		vddwlmx-supply = <&vreg_pmu_wlmx_0p85>;
		vddrfa0p8-supply = <&vreg_pmu_rfa_0p8>;
		vddrfa1p2-supply = <&vreg_pmu_rfa_1p2>;
		vddrfa1p8-supply = <&vreg_pmu_rfa_1p8>;

		max-speed = <3200000>;
	};
};

&pm8550_flash {
	status = "okay";
	
	led-0 {
		function = LED_FUNCTION_FLASH;
		color = <LED_COLOR_ID_WHITE>;
		led-sources = <1>, <4>;
		led-max-microamp = <500000>;
		flash-max-microamp = <2000000>;
		flash-max-timeout-us = <1280000>;
		function-enumerator = <0>;
	};
};

&i2c8 {
	status = "okay";
	bq28z610: fuel-gauge@55 {
		compatible = "ti,bq28z610";
		reg = <0x55>;
		monitored-battery = <&bat>;
	};
};

&i2c6 {
	status = "okay";

	top_speaker: codec@34 {
		reg = <0x34>;
		compatible = "nxp,tfa9873";

		reset-gpio = <&tlmm 56 GPIO_ACTIVE_HIGH>;

		#sound-dai-cells = <0>;
	};

	bottom_speaker: codec@35 {
		reg = <0x35>;
		compatible = "nxp,tfa9873";

		reset-gpio = <&tlmm 173 GPIO_ACTIVE_HIGH>;
		is_second_channel;

		#sound-dai-cells = <0>;
	};
};

&swr1 {
	status = "okay";
	/* WCD9380 RX */
	wcd_rx: codec@0,4 {
		compatible = "sdw20217010d00";
		reg = <0 4>;
		qcom,rx-port-mapping = <1 2 3 4 5>;
	};
};

&swr2 {
	status = "okay";
	/* WCD9380 TX */
	wcd_tx: codec@0,3 {
		compatible = "sdw20217010d00";
		reg = <0 3>;
		qcom,tx-port-mapping = <2 2 3 4>;
	};
};

&i2c0 {
	status = "okay";
	nfc: sn-nci@28 {
		compatible = "qcom,sn-nci", "nxp,nxp-nci-i2c";
		reg = <0x28>;
		qcom,sn-irq = <&tlmm 55 GPIO_ACTIVE_HIGH>;
		enable-gpios = <&tlmm 30 GPIO_ACTIVE_HIGH>;
		qcom,sn-clkreq = <&tlmm 31 GPIO_ACTIVE_HIGH>;
		interrupt-parent = <&tlmm>;
		interrupts = <55 0>;
		interrupt-names = "nfc_irq";
		pinctrl-names = "default", "sleep";
		pinctrl-0 = <&nfc_default>;
		pinctrl-1 = <&nfc_sleep>;
	};
};

&i2c9 {
	status = "okay";
	magnachip: magnachip@10 {
		compatible = "oplus,dhall-ak09970";
		reg = <0x10>;
		vcc-supply = <&vreg_l1b_1p8>;
		interrupt-parent = <&tlmm>;
		interrupts = <17 2>;
		threeaxis_hall_support;
		dhall,irq-gpio = <&tlmm 17 0x2008>;
		pinctrl-names = "hall_interrupt_input";
		pinctrl-0 = <&hall_interrupt_input>;
	};
};

&i2c_master_hub_0 {
	status = "okay";
};

&i2c_hub_2 {
	status = "okay";

	typec-mux@42 {
		compatible = "fcs,fsa4480";
		reg = <0x42>;

		vcc-supply = <&vreg_bob1>;

		mode-switch;
		orientation-switch;

		port {
			fsa4480_sbu_mux: endpoint {
				remote-endpoint = <&pmic_glink_sbu>;
			};
		};
	};
};

&spi4 {
	status = "okay";
	synaptics_tcm_hbp@0 {
		compatible = "synaptics,tcm-spi-hbp";
		reg = <0>;
		spi-max-frequency = <19000000>;
		interrupt-parent = <&tlmm>;
		interrupts = <25 0x2008>;
		vdd-supply = <&vreg_l4b_1p8>;
		synaptics,irq-gpio = <&tlmm 25 0x2008>;
		synaptics,reset-gpio = <&tlmm 24 GPIO_ACTIVE_HIGH>;
		synaptics,avdd-gpio = <&tlmm 10 GPIO_ACTIVE_HIGH>;
		pinctrl-names = "ts_spi_active", "ts_spi_suspend";
		pinctrl-0 = <&ts_int_active &ts_reset_active>;
		pinctrl-1 = <&ts_int_suspend &ts_reset_suspend>;
		touchpanel,panel-coords = <20224 44480>;
		touchpanel,tx-rx-num = <17 38>;
		touchpanel,tp_ic_type = <2>;
	};
};

&gpi_dma1 {
	status = "okay";
};

&gpi_dma2 {
	status = "okay";
};

&pm8550b_eusb2_repeater {
	vdd18-supply = <&vreg_l15b_1p8>;
	vdd3-supply = <&vreg_l5b_3p1>;
};

&videocc {
	power-domains = <&rpmhpd SM8550_MXC>;
};

&camss {
	vdda-phy-supply = <&vreg_l1e_0p88>;
	vdda-pll-supply = <&vreg_l3e_1p2>;

	status = "okay";

	ports {
		#address-cells = <1>;
		#size-cells = <0>;

		port@1 {
			reg = <1>;

			csiphy1_ep: endpoint {
				data-lanes = <0 1 2 3>;
				remote-endpoint = <&s5k3p9_ep>;
			};
		};

		port@3 {
			reg = <3>;

			csiphy3_ep: endpoint {
				data-lanes = <0 1 2 3>;
				remote-endpoint = <&imx355_ep>;
			};
		};

		port@4 {
			reg = <4>;

			csiphy4_ep: endpoint {
				data-lanes = <0>;
				remote-endpoint = <&ov02b1b_ep>;
			};
		};
	};
};

&cci0 {
	status = "okay";
};

&cci1 {
	status = "okay";
};

// Ultrawide camera
&cci0_i2c1 {
	clock-frequency = <400000>;
	status = "okay";
	camera@1a {
		compatible = "sony,imx355";
		reg = <0x1a>;

		reset-gpios = <&tlmm 118 GPIO_ACTIVE_HIGH>;
		pinctrl-names = "default";
		pinctrl-0 = <&cam_mclk1_default>, <&cam_uw_reset_default>;

		clocks = <&camcc CAM_CC_MCLK1_CLK>;
		clock-names = "mclk";
		clock-frequency = <19200000>;

		vana-supply = <&vreg_l6m_2p8>;
		vdig-supply = <&vreg_l2m_1p08>;
		vio-supply = <&vreg_l10b_1p8>;

		orientation = <1>;
		rotation = <90>;

		port {
			imx355_ep: endpoint {
				data-lanes = <0 1 2 3>;
				link-frequencies = /bits/ 64 <360000000>;
				remote-endpoint = <&csiphy3_ep>;
			};
		};
	};
};

// Macro/Tele- camera
&cci1_i2c0 {
	clock-frequency = <400000>;
	status = "okay";
	camera@3d {
		compatible = "ovti,ov02b1b";
		reg = <0x3d>;

		reset-gpios = <&tlmm 119 GPIO_ACTIVE_LOW>;
		pinctrl-names = "default";
		pinctrl-0 = <&cam_mclk0_default>, <&cam_tele_reset_default>;

		clocks = <&camcc CAM_CC_MCLK0_CLK>;
		clock-names = "mclk";
		clock-frequency = <19200000>;

		avdd-supply = <&vreg_l4m_2p8>;
		vddio-supply = <&vreg_l10b_1p8>;

		orientation = <1>;
		rotation = <90>;

		port {
			ov02b1b_ep: endpoint {
				data-lanes = <0>;
				link-frequencies = /bits/ 64 <332800000>;
				remote-endpoint = <&csiphy4_ep>;
			};
		};
	};
};

// Front camera
&cci1_i2c1 {
	clock-frequency = <1000000>;
	status = "okay";
	camera@10 {
		compatible = "samsung,s5k3p9";
		reg = <0x10>;

		reset-gpios = <&tlmm 120 GPIO_ACTIVE_LOW>;
		pinctrl-names = "default";
		pinctrl-0 = <&cam_mclk4_default>, <&cam_front_reset_default>;

		clocks = <&camcc CAM_CC_MCLK4_CLK>;
		clock-names = "mclk";
		clock-frequency = <19200000>;

		vana-supply = <&vreg_l4m_2p8>;
		vdig-supply = <&vreg_l2g_1p2>;
		vio-supply = <&vreg_l10b_1p8>;

		orientation = <0>;
		rotation = <270>;

		port {
			s5k3p9_ep: endpoint {
				data-lanes = <0 1 2 3>;
				link-frequencies = /bits/ 64 <600000000>;
				remote-endpoint = <&csiphy1_ep>;
			};
		};
	};
};
